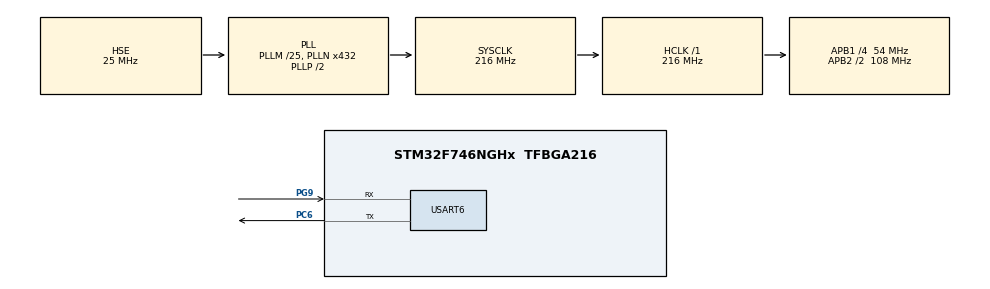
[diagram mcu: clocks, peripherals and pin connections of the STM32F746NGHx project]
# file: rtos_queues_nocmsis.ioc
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FREERTOS.Tasks01=defaultTask,0,128,StartDefaultTask,Default,NULL,Dynamic,NULL,NULL
Mcu.Family=STM32F7
Mcu.Name=STM32F746NGHx
Mcu.Package=TFBGA216
NVIC.PriorityGroup=NVIC_PRIORITYGROUP_4
NVIC.TIM1_UP_TIM10_IRQn=true\:15\:0\:false\:false\:true\:false\:false\:true\:true
NVIC.TimeBase=TIM1_UP_TIM10_IRQn
NVIC.TimeBaseIP=TIM1
PC6.Mode=Asynchronous
PC6.Signal=USART6_TX
PG9.Mode=Asynchronous
PG9.Signal=USART6_RX
PH0/OSC_IN.Mode=HSE-External-Oscillator
PH0/OSC_IN.Signal=RCC_OSC_IN
PH1/OSC_OUT.Mode=HSE-External-Oscillator
PH1/OSC_OUT.Signal=RCC_OSC_OUT
ProjectManager.HeapSize=0x200
ProjectManager.StackSize=0x400
ProjectManager.TargetToolchain=STM32CubeIDE
RCC.AHBFreq_Value=216000000
RCC.APB1CLKDivider=RCC_HCLK_DIV4
RCC.APB1Freq_Value=54000000
RCC.APB1TimFreq_Value=108000000
RCC.APB2CLKDivider=RCC_HCLK_DIV2
RCC.APB2Freq_Value=108000000
RCC.APB2TimFreq_Value=216000000
RCC.CortexFreq_Value=216000000
RCC.HCLKFreq_Value=216000000
RCC.HSE_VALUE=25000000
RCC.HSI_VALUE=16000000
RCC.PLL48CLockSelection=RCC_CLK48SOURCE_PLLSAIP
RCC.PLLI2SN=100
RCC.PLLM=25
RCC.PLLN=432
RCC.PLLQ=9
RCC.PLLSAIN=384
RCC.PLLSAIP=RCC_PLLSAIP_DIV8
RCC.PLLSAIR=5
RCC.PLLSAIRDiv=RCC_PLLSAIDIVR_8
RCC.PLLSourceVirtual=RCC_PLLSOURCE_HSE
RCC.SDMMCClockSelection=RCC_SDMMC1CLKSOURCE_CLK48
RCC.SYSCLKFreq_VALUE=216000000
RCC.SYSCLKSource=RCC_SYSCLKSOURCE_PLLCLK
RCC.USBFreq_Value=48000000
RCC.VCOOutputFreq_Value=432000000
USART6.VirtualMode-Asynchronous=VM_ASYNC
VP_FREERTOS_VS_CMSIS_V1.Mode=CMSIS_V1
VP_SYS_VS_tim1.Mode=TIM1
board=STM32F746G-DISCO

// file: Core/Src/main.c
/* USER CODE BEGIN Header */
/**
  ******************************************************************************
  * @file           : main.c
  * @brief          : Main program body
  ******************************************************************************
  * @attention
  *
  * Copyright (c) 2025 STMicroelectronics.
  * All rights reserved.
  *
  * This software is licensed under terms that can be found in the LICENSE file
  * in the root directory of this software component.
  * If no LICENSE file comes with this software, it is provided AS-IS.
  *
  ******************************************************************************
  */
/* USER CODE END Header */
#include "main.h"

/* USER CODE BEGIN Includes */
#include "FreeRTOS.h"
#include "task.h"
#include "timers.h"
#include "queue.h"
#include "semphr.h"
#include "event_groups.h"
#include "stdio.h"
#include "string.h"
/* USER CODE END Includes */

UART_HandleTypeDef huart6;

void SystemClock_Config(void);
static void MX_GPIO_Init(void);
static void MX_USART6_UART_Init(void);

/* USER CODE BEGIN 0 */
/****************TASK HANDLERS ****************************/
xTaskHandle Sender_HPT_Handler;
xTaskHandle Sender_LPT_Handler;
xTaskHandle Receiver_Handler;

/****************QUEUE HANDLERS ***************************/
xQueueHandle SimpleQueue;

/****************TASK FUNCTIONS ***************************/
void Sender_HPT_Task (void *argument);
void Sender_LPT_Task (void *argument);
void Receiver_Task (void *argument);

uint8_t rx_data;
/* USER CODE END 0 */

int main(void)
{

  /* MCU Configuration--------------------------------------------------------*/

  /* Reset of all peripherals, Initializes the Flash interface and the Systick. */
  HAL_Init();

  /* Configure the system clock */
  SystemClock_Config();

  /* Initialize all configured peripherals */
  MX_GPIO_Init();
  MX_USART6_UART_Init();
  /* USER CODE BEGIN 2 */
 /***************CREATE INTEGER QUEUE *********************************/
  SimpleQueue = xQueueCreate(5, sizeof(int));
  if(SimpleQueue == 0)  //Queue not created
  {
	  char *str= "Unable to create Integer Queue\r\n";
	  HAL_UART_Transmit(&huart6, (uint8_t *)str, strlen(str), HAL_MAX_DELAY);
  }
  else
  {
	  char *str= "Integer Queue created\r\n";
	  HAL_UART_Transmit(&huart6, (uint8_t *)str, strlen(str), HAL_MAX_DELAY);
  }

  /**************TASK RELATED *****************************************/
  xTaskCreate(Sender_HPT_Task, "HPT_SEND", 128, NULL, 3, &Sender_HPT_Handler);
  xTaskCreate(Sender_LPT_Task, "LPT_SEND", 128, (void *)111, 2, &Sender_LPT_Handler);
  xTaskCreate(Receiver_Task, "Receive", 128, NULL, 1, &Receiver_Handler);

  HAL_UART_Receive_IT(&huart6, &rx_data, 1);
  vTaskStartScheduler();
  /* USER CODE END 2 */

  /* We should never get here as control is now taken by the scheduler */

  /* Infinite loop */
  while (1)
  {

  }
}

void SystemClock_Config(void)
{
  RCC_OscInitTypeDef RCC_OscInitStruct = {0};
  RCC_ClkInitTypeDef RCC_ClkInitStruct = {0};

  /** Configure the main internal regulator output voltage
  */
  __HAL_RCC_PWR_CLK_ENABLE();
  __HAL_PWR_VOLTAGESCALING_CONFIG(PWR_REGULATOR_VOLTAGE_SCALE1);

  /** Initializes the RCC Oscillators according to the specified parameters
  * in the RCC_OscInitTypeDef structure.
  */
  RCC_OscInitStruct.OscillatorType = RCC_OSCILLATORTYPE_HSE;
  RCC_OscInitStruct.HSEState = RCC_HSE_ON;
  RCC_OscInitStruct.PLL.PLLState = RCC_PLL_ON;
  RCC_OscInitStruct.PLL.PLLSource = RCC_PLLSOURCE_HSE;
  RCC_OscInitStruct.PLL.PLLM = 25;
  RCC_OscInitStruct.PLL.PLLN = 432;
  RCC_OscInitStruct.PLL.PLLP = RCC_PLLP_DIV2;
  RCC_OscInitStruct.PLL.PLLQ = 9;
  if (HAL_RCC_OscConfig(&RCC_OscInitStruct) != HAL_OK)
  {
    Error_Handler();
  }

  /** Activate the Over-Drive mode
  */
  if (HAL_PWREx_EnableOverDrive() != HAL_OK)
  {
    Error_Handler();
  }

  /** Initializes the CPU, AHB and APB buses clocks
  */
  RCC_ClkInitStruct.ClockType = RCC_CLOCKTYPE_HCLK|RCC_CLOCKTYPE_SYSCLK
                              |RCC_CLOCKTYPE_PCLK1|RCC_CLOCKTYPE_PCLK2;
  RCC_ClkInitStruct.SYSCLKSource = RCC_SYSCLKSOURCE_PLLCLK;
  RCC_ClkInitStruct.AHBCLKDivider = RCC_SYSCLK_DIV1;
  RCC_ClkInitStruct.APB1CLKDivider = RCC_HCLK_DIV4;
  RCC_ClkInitStruct.APB2CLKDivider = RCC_HCLK_DIV2;

  if (HAL_RCC_ClockConfig(&RCC_ClkInitStruct, FLASH_LATENCY_7) != HAL_OK)
  {
    Error_Handler();
  }
}

static void MX_USART6_UART_Init(void)
{

  huart6.Instance = USART6;
  huart6.Init.BaudRate = 115200;
  huart6.Init.WordLength = UART_WORDLENGTH_8B;
  huart6.Init.StopBits = UART_STOPBITS_1;
  huart6.Init.Parity = UART_PARITY_NONE;
  huart6.Init.Mode = UART_MODE_TX_RX;
  huart6.Init.HwFlowCtl = UART_HWCONTROL_NONE;
  huart6.Init.OverSampling = UART_OVERSAMPLING_16;
  huart6.Init.OneBitSampling = UART_ONE_BIT_SAMPLE_DISABLE;
  huart6.AdvancedInit.AdvFeatureInit = UART_ADVFEATURE_NO_INIT;
  if (HAL_UART_Init(&huart6) != HAL_OK)
  {
    Error_Handler();
  }

}

static void MX_GPIO_Init(void)
{

  /* GPIO Ports Clock Enable */
  __HAL_RCC_GPIOG_CLK_ENABLE();
  __HAL_RCC_GPIOH_CLK_ENABLE();
  __HAL_RCC_GPIOC_CLK_ENABLE();

}

/* USER CODE BEGIN 4 */
void Sender_HPT_Task (void *argument)
{
	int i=222;
	uint32_t TickDelay = pdMS_TO_TICKS(2000);
	while(1)
	{
		char *str = "Entered SENDER_HPT Task\r\n about to send a number to the queue \r\n";
		HAL_UART_Transmit(&huart6, (uint8_t *)str, strlen(str), HAL_MAX_DELAY);

		if(xQueueSend(SimpleQueue, &i, portMAX_DELAY) == pdPASS)
		{
			char *str2 = "Successfully sent the number to the queue\r\n Leaving SENDER_HPT Task \r\n  \r\n ";
			HAL_UART_Transmit(&huart6, (uint8_t *)str2, strlen (str2), HAL_MAX_DELAY);
		}
		vTaskDelay(TickDelay);
	}
}

void Sender_LPT_Task (void *argument)
{
	int ToSend;
	uint32_t TickDelay = pdMS_TO_TICKS(1000);
	while(1)
	{
		ToSend = (int) argument;
		char *str = "Entered SENDER_LPT Task\r\n about to SEND a number to the queue \r\n";
		HAL_UART_Transmit(&huart6, (uint8_t *)str, strlen(str), HAL_MAX_DELAY);

		if(xQueueSend(SimpleQueue, &ToSend, portMAX_DELAY) == pdPASS)
		{
			char *str2 = "Successfully sent the number to the queue\r\n Leaving SENDER_LPT Task \r\n \r\n ";
			HAL_UART_Transmit(&huart6, (uint8_t *)str2, strlen (str2), HAL_MAX_DELAY);
		}
		vTaskDelay(TickDelay);
	}
}

void Receiver_Task (void *argument)
{
	int received = 0;
	uint32_t TickDelay = pdMS_TO_TICKS(5000);
	while(1)
	{
		char str[100];
		strcpy(str, "Entered RECEIVER Task\r\n About to RECEIVE a number from the queue\r\n");
		HAL_UART_Transmit(&huart6, (uint8_t *)str, strlen(str), HAL_MAX_DELAY);

		if(xQueueReceive(SimpleQueue, &received, portMAX_DELAY) != pdTRUE)
		{
			HAL_UART_Transmit(&huart6, (uint8_t *)"Error in Receiving from Queue \r\n", 31 , 1000);
		}
		else
		{
			sprintf(str, "Successfully RECEIVED the number %d to the queue\r\n Leaving RECEIVER Task \r\n", received);
			HAL_UART_Transmit(&huart6, (uint8_t *)str, strlen(str), HAL_MAX_DELAY);
		}
		vTaskDelay(TickDelay);
	}
}
//
//void HAL_RxCpltCallback(UART_HandleTypeDef *huart)
//{
//	HAL_UART_Receive_IT(huartm &rx_data, 1);
//	int ToSend=123456789;
//	if(rx_data == 'r')
//	{
//		/*The xHigherPriorityTaskWoken parameter must be initialized to pdFALSE as it will get set to pdTRUE
//		 * inside the interrupt sage API function if a context switch is required*/
//		BaseType_t xHigherPriorityTaskWoken = pdFALSE;
//
//		if(xQueueSendToFrontFromISR(SimpleQueue, &ToSend, &HigherPriorityTaskWoken) == pdPASS)
//		{
//			HAL_UART_Transmit(huart, (uint8_t *)"\n\nSent from ISR\r\n", 17, 500);
//		}
//		/*Pass the xHigherPriorityTaskWoken value into portEND_SWITCHING_ISR().
//		  If xHigherPriorityTaskWoken was set to pdTRUE inside xSemaphoreGiveFromISR()
//		  xHigherPriorityTaskWoken is still pdFALSE then calling portEND_SWITCHING_ISR()
//		  will have no effect*/
//
//		portEND_SWITCHING_ISR(xHigherPriorityTaskWoken);
//	}
//}

/* USER CODE END 4 */

void HAL_TIM_PeriodElapsedCallback(TIM_HandleTypeDef *htim)
{
  if (htim->Instance == TIM1)
  {
    HAL_IncTick();
  }
}

void Error_Handler(void)
{
  __disable_irq();
  while (1)
  {
  }
}
